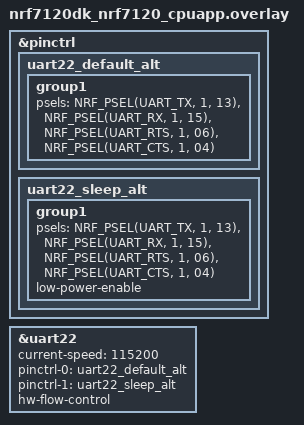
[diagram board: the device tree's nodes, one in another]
/*
 * Copyright (c) 2026 Nordic Semiconductor ASA
 *
 * SPDX-License-Identifier: Apache-2.0
 */

&pinctrl {
	uart22_default_alt: uart22_default_alt {
		group1 {
			psels = <NRF_PSEL(UART_TX, 1, 13)>,
				<NRF_PSEL(UART_RX, 1, 15)>,
				<NRF_PSEL(UART_RTS, 1, 06)>,
				<NRF_PSEL(UART_CTS, 1, 04)>;
		};
	};

	uart22_sleep_alt: uart22_sleep_alt {
		group1 {
			psels = <NRF_PSEL(UART_TX, 1, 13)>,
				<NRF_PSEL(UART_RX, 1, 15)>,
				<NRF_PSEL(UART_RTS, 1, 06)>,
				<NRF_PSEL(UART_CTS, 1, 04)>;
			low-power-enable;
		};
	};
};

dut: &uart22 {
	status = "okay";
	current-speed = <115200>;
	pinctrl-0 = <&uart22_default_alt>;
	pinctrl-1 = <&uart22_sleep_alt>;
	pinctrl-names = "default", "sleep";
	hw-flow-control;
};
